# FSS0_FSAS_0_OTFA_CFG register map
Vendor: Texas Instruments
Peripheral module from a debugger description file (folder J722S).
Registers are 32-bit, read-write, reset 0x0 unless marked. A register's access mark holds for its fields unless they carry their own. Offsets are as the file gives them; lines under a group give offsets from that group; [hi:lo] are bit positions; {n}, {i} and the like mark numbered series; 'fields as' and 'values as' point back to an identical list; <NAME> marks a mode.

## FSS0_FSAS_0_OTFA_CFG
0x00 FSAS__FSAS_OTFA_CFG__FSAS_OTFA_REGS_revid ro reset 0x47500100
0x04 FSAS__FSAS_OTFA_CFG__FSAS_OTFA_REGS_scfg reset 0x2
  [1:0] IDLE_MODE
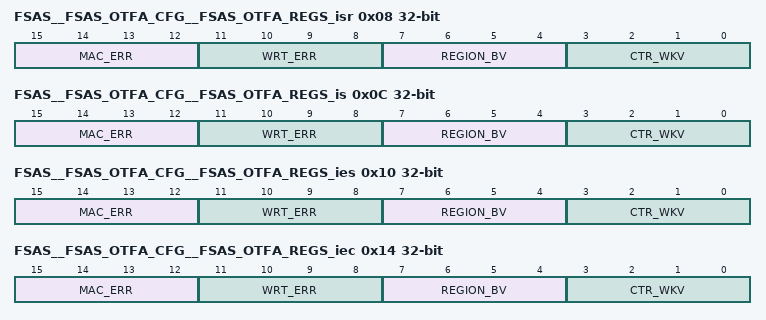
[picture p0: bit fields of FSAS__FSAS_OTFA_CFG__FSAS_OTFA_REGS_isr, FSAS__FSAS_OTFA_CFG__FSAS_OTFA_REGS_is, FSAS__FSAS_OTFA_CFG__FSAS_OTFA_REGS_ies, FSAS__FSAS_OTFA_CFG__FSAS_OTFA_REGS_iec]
0x08 FSAS__FSAS_OTFA_CFG__FSAS_OTFA_REGS_isr
  [15:12] MAC_ERR — MAC error
  [11:8] WRT_ERR — Write error
  [7:4] REGION_BV — Region overflow boundary event caused by a burst transaction crossed a start or end of a region
  [3:0] CTR_WKV — AES mode 0 enabled region violated Wrt Once Per Wrt Key rule
0x0C FSAS__FSAS_OTFA_CFG__FSAS_OTFA_REGS_is
  fields as FSAS__FSAS_OTFA_CFG__FSAS_OTFA_REGS_isr
0x10 FSAS__FSAS_OTFA_CFG__FSAS_OTFA_REGS_ies
  fields as FSAS__FSAS_OTFA_CFG__FSAS_OTFA_REGS_isr
0x14 FSAS__FSAS_OTFA_CFG__FSAS_OTFA_REGS_iec
  fields as FSAS__FSAS_OTFA_CFG__FSAS_OTFA_REGS_isr
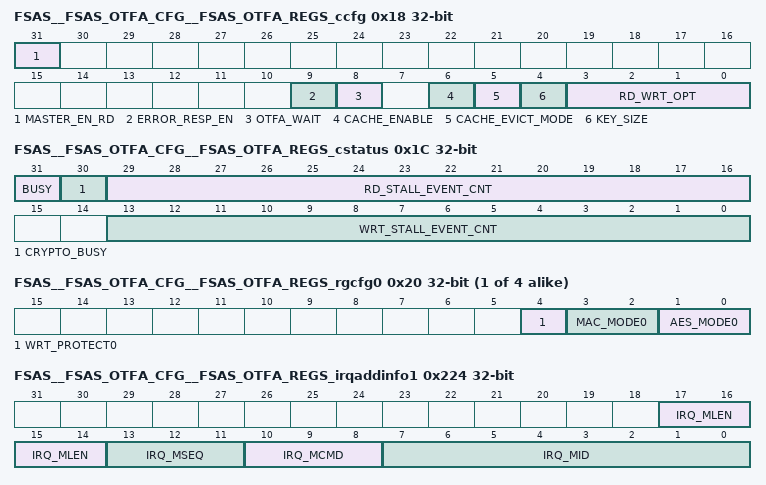
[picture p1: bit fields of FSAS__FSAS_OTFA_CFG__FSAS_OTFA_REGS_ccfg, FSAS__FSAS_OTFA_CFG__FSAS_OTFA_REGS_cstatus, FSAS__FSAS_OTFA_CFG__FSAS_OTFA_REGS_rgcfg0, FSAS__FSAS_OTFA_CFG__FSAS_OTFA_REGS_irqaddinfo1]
0x18 FSAS__FSAS_OTFA_CFG__FSAS_OTFA_REGS_ccfg
  [31] MASTER_EN_RD — This register controls the enabling the functionality of this IP Disabled and Bypass mode active
  [9] ERROR_RESP_EN — This register controls the enabling the the ocp error response for mac errors
  [8] OTFA_WAIT — This register allows the ability to stop accepting any new transactions from getting accepted and allow the current transactions to complete
  [6] CACHE_ENABLE — MAC cache enable
  [5] CACHE_EVICT_MODE
  [4] KEY_SIZE — Key Size, 0 128 Bit 1 256 Bit
  [3:0] RD_WRT_OPT — This register defines the static allocation of the AES cores to read transactions. The remainder will be allocated to write transactions
0x1C FSAS__FSAS_OTFA_CFG__FSAS_OTFA_REGS_cstatus access not given
  [31] BUSY ro — 0 No transactions are active, crypto or none crypto 1 One or more transactions are active, crypto or none crypto
  [30] CRYPTO_BUSY ro — 0 No transactions are active, crypto or none crypto 1 One or more transactions are active, crypto or none crypto
  [29:16] RD_STALL_EVENT_CNT — rd stall event do to lack of eng (access R/W1TC)
  [13:0] WRT_STALL_EVENT_CNT — wrt stall event do to lack of eng (access R/W1TC)
{0x20+0x80*i} FSAS__FSAS_OTFA_CFG__FSAS_OTFA_REGS_rgcfg{i} (i=0..3)
  [4] WRT_PROTECT{i} — WRT protect
  [3:2] MAC_MODE{i} — MAC mode
  [1:0] AES_MODE{i} — AES mode
{0x24+0x80*i} FSAS__FSAS_OTFA_CFG__FSAS_OTFA_REGS_rgmacst{i} (i=0..3)
  [19:0] M_START{i} — This defines the start of the mac buffer in 4KBytes steps
{0x28+0x80*i} FSAS__FSAS_OTFA_CFG__FSAS_OTFA_REGS_rgst{i} (i=0..3)
  [19:0] R_START{i} — This defines the start of the crypto region in 4KBytes steps
{0x2C+0x80*i} FSAS__FSAS_OTFA_CFG__FSAS_OTFA_REGS_rgsi{i} (i=0..3)
  [19:0] R_SIZE{i} — This defines the size of the crypto region in 4KBytes steps
{0x30+4i} FSAS__FSAS_OTFA_CFG__FSAS_OTFA_REGS_rkeye{i:02} (i=0..7)
  [31:0] R_KEY_E{i:02} — Key E
{0x50+4i} FSAS__FSAS_OTFA_CFG__FSAS_OTFA_REGS_rkeyep{i:02} (i=0..7)
  [31:0] R_KEY_EP{i:02} — Key EP
{0x70+4i} FSAS__FSAS_OTFA_CFG__FSAS_OTFA_REGS_rkeya{i:02} (i=0..3)
  [31:0] R_KEY_A{i:02} — Key A
{0x80+4i} FSAS__FSAS_OTFA_CFG__FSAS_OTFA_REGS_rkeyap{i:02} (i=0..3)
  [31:0] R_KEY_AP{i:02} — Key AP
{0x90+4i} FSAS__FSAS_OTFA_CFG__FSAS_OTFA_REGS_riv{i:02} (i=0..3)
  [31:0] R_IV{i:02} — IV
{0x88+4i} FSAS__FSAS_OTFA_CFG__FSAS_OTFA_REGS_rkeye{i} (i=10..17)
  [31:0] R_KEY_E{i} — Key E
{0xA8+4i} FSAS__FSAS_OTFA_CFG__FSAS_OTFA_REGS_rkeyep{i} (i=10..17)
  [31:0] R_KEY_EP{i} — Key EP
{0xC8+4i} FSAS__FSAS_OTFA_CFG__FSAS_OTFA_REGS_rkeya{i} (i=10..13)
  [31:0] R_KEY_A{i} — Key A
{0xD8+4i} FSAS__FSAS_OTFA_CFG__FSAS_OTFA_REGS_rkeyap{i} (i=10..13)
  [31:0] R_KEY_AP{i} — Key AP
{0xE8+4i} FSAS__FSAS_OTFA_CFG__FSAS_OTFA_REGS_riv{i} (i=10..13)
  [31:0] R_IV{i} — IV
{0xE0+4i} FSAS__FSAS_OTFA_CFG__FSAS_OTFA_REGS_rkeye{i} (i=20..27)
  [31:0] R_KEY_E{i} — Key E
{0x100+4i} FSAS__FSAS_OTFA_CFG__FSAS_OTFA_REGS_rkeyep{i} (i=20..27)
  [31:0] R_KEY_EP{i} — Key EP
{0x120+4i} FSAS__FSAS_OTFA_CFG__FSAS_OTFA_REGS_rkeya{i} (i=20..23)
  [31:0] R_KEY_A{i} — Key A
{0x130+4i} FSAS__FSAS_OTFA_CFG__FSAS_OTFA_REGS_rkeyap{i} (i=20..23)
  [31:0] R_KEY_AP{i} — Key AP
{0x140+4i} FSAS__FSAS_OTFA_CFG__FSAS_OTFA_REGS_riv{i} (i=20..23)
  [31:0] R_IV{i} — IV
{0x138+4i} FSAS__FSAS_OTFA_CFG__FSAS_OTFA_REGS_rkeye{i} (i=30..37)
  [31:0] R_KEY_E{i} — Key E
{0x158+4i} FSAS__FSAS_OTFA_CFG__FSAS_OTFA_REGS_rkeyep{i} (i=30..37)
  [31:0] R_KEY_EP{i} — Key EP
{0x178+4i} FSAS__FSAS_OTFA_CFG__FSAS_OTFA_REGS_rkeya{i} (i=30..33)
  [31:0] R_KEY_A{i} — Key A
{0x188+4i} FSAS__FSAS_OTFA_CFG__FSAS_OTFA_REGS_rkeyap{i} (i=30..33)
  [31:0] R_KEY_AP{i} — Key AP
{0x198+4i} FSAS__FSAS_OTFA_CFG__FSAS_OTFA_REGS_riv{i} (i=30..33)
  [31:0] R_IV{i} — IV
0x220 FSAS__FSAS_OTFA_CFG__FSAS_OTFA_REGS_irqaddinfo0 ro
  [31:0] IRQ_MADDR — Initiator Address which caused the event
0x224 FSAS__FSAS_OTFA_CFG__FSAS_OTFA_REGS_irqaddinfo1 ro
  [17:14] IRQ_MLEN — Initiator LENGTH which caused the event
  [13:11] IRQ_MSEQ — Initiator SEQ which caused the event
  [10:8] IRQ_MCMD — Initiator CMD which caused the event
  [7:0] IRQ_MID — Initiator TAG ID which caused the event
0x228 FSAS__FSAS_OTFA_CFG__FSAS_OTFA_REGS_maccacheinfo ro
  [15:0] CACHE_MISS_EVENT_CNT — MAC Cache Miss event cnt
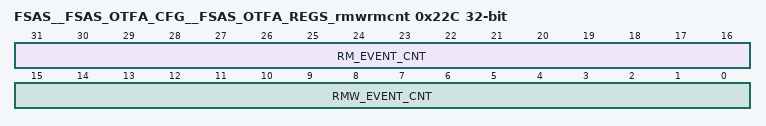
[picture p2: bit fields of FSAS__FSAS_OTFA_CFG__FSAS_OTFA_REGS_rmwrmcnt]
0x22C FSAS__FSAS_OTFA_CFG__FSAS_OTFA_REGS_rmwrmcnt ro
  [31:16] RM_EVENT_CNT, [15:0] RMW_EVENT_CNT
